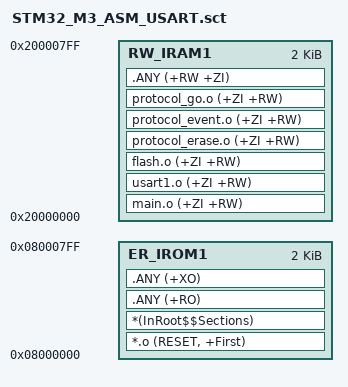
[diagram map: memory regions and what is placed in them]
; *************************************************************
; *** Scatter-Loading Description File generated by uVision ***
; *************************************************************

LR_IROM1 0x08000000 0x00000800  {    ; load region size_region
  ER_IROM1 0x08000000 0x00000800  {  ; load address = execution address
   *.o (RESET, +First)
   *(InRoot$$Sections)
   .ANY (+RO)
   .ANY (+XO)
  }
  RW_IRAM1 0x20000000 0x00000800  {  ; RW data
    main.o (+ZI +RW)
    usart1.o (+ZI +RW)
    flash.o (+ZI +RW)
    protocol_erase.o (+ZI +RW)
    protocol_event.o (+ZI +RW)
    protocol_go.o (+ZI +RW)
   .ANY (+RW +ZI)
  }
}

